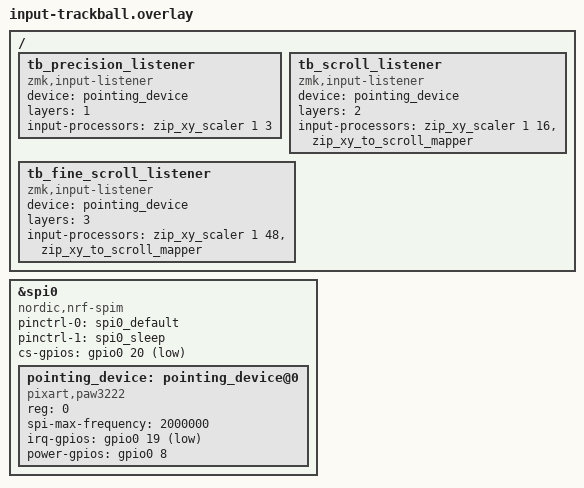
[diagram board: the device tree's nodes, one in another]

&spi0 {
    status = "okay";
    compatible = "nordic,nrf-spim";
    pinctrl-0 = <&spi0_default>;
    pinctrl-1 = <&spi0_sleep>;
    pinctrl-names = "default", "sleep";
    cs-gpios = <&gpio0 20 GPIO_ACTIVE_LOW>;

    pointing_device: pointing_device@0 {
        status = "okay";
        compatible = "pixart,paw3222";
        reg = <0>;
        spi-max-frequency = <2000000>;
        irq-gpios = <&gpio0 19 GPIO_ACTIVE_LOW>;
        power-gpios = <&gpio0 8 (GPIO_ACTIVE_HIGH | NRF_GPIO_DRIVE_H0H1)>;
    };
};

/* ▼ここから追加：トラックボールが存在する時のみリスナーを有効化▼ */
/ {
    tb_precision_listener {
        compatible = "zmk,input-listener";
        device = <&pointing_device>;
        layers = <1>;
        input-processors = <&zip_xy_scaler 1 3>;
    };

    tb_scroll_listener {
        compatible = "zmk,input-listener";
        device = <&pointing_device>;
        layers = <2>;
        input-processors = 
            <&zip_xy_scaler 1 16>,
            <&zip_xy_to_scroll_mapper>;
    };

    tb_fine_scroll_listener {
        compatible = "zmk,input-listener";
        device = <&pointing_device>;
        layers = <3>;
        input-processors = 
            <&zip_xy_scaler 1 48>,
            <&zip_xy_to_scroll_mapper>;
    };
};
